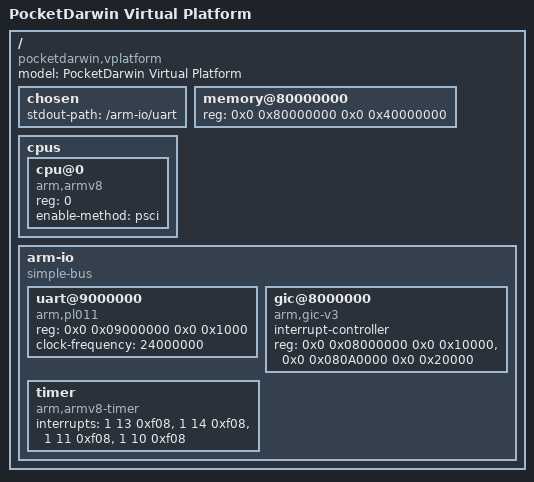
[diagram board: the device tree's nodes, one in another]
/dts-v1/;

/ {
    model = "PocketDarwin Virtual Platform";
    compatible = "pocketdarwin,vplatform";

    #address-cells = <2>;
    #size-cells = <2>;

    chosen {
        stdout-path = "/arm-io/uart";
    };

    memory@80000000 {
        device_type = "memory";
        reg = <0x0 0x80000000  0x0 0x40000000>; /* 1GB */
    };

    cpus {
        #address-cells = <1>;
        #size-cells = <0>;

        cpu@0 {
            device_type = "cpu";
            compatible = "arm,armv8";
            reg = <0>;
            enable-method = "psci";
        };
    };

    arm-io {
        compatible = "simple-bus";
        #address-cells = <2>;
        #size-cells = <2>;
        ranges;

        uart@9000000 {
            compatible = "arm,pl011";
            reg = <0x0 0x09000000 0x0 0x1000>;
            clock-frequency = <24000000>;
        };

        gic@8000000 {
            compatible = "arm,gic-v3";
            interrupt-controller;
            #interrupt-cells = <3>;
            reg = <0x0 0x08000000 0x0 0x10000>,
                  <0x0 0x080A0000 0x0 0x20000>;
        };

	timer {
	   compatible = "arm,armv8-timer";
	   interrupts = <1 13 0xf08>,
			<1 14 0xf08>,
			<1 11 0xf08>,
			<1 10 0xf08>;
	};
    };
};

